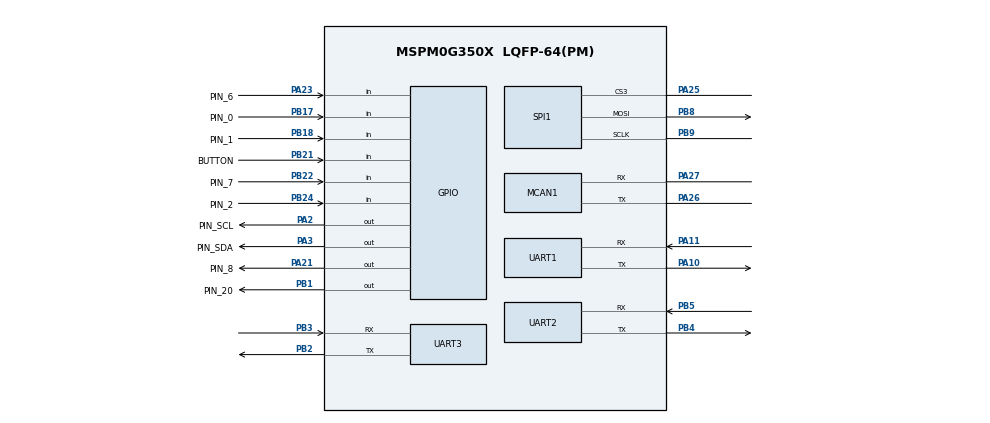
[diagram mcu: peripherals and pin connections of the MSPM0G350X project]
/**
 * @cliArgs --device "MSPM0G350X" --part "Default" --package "LQFP-64(PM)" --product "mspm0_sdk@2.05.01.01"
 * @versions {"tool":"1.24.0+4110"}
 */

/**
 * Import the modules used in this configuration.
 */
const GPIO   = scripting.addModule("/ti/driverlib/GPIO", {}, false);
const GPIO1  = GPIO.addInstance();
const GPIO2  = GPIO.addInstance();
const GPIO3  = GPIO.addInstance();
const GPIO4  = GPIO.addInstance();
const GPIO5  = GPIO.addInstance();
const GPIO6  = GPIO.addInstance();
const GPIO7  = GPIO.addInstance();
const GPIO8  = GPIO.addInstance();
const GPIO9  = GPIO.addInstance();
const GPIO10 = GPIO.addInstance();
const PWM    = scripting.addModule("/ti/driverlib/PWM", {}, false);
const PWM1   = PWM.addInstance();
const MCAN   = scripting.addModule("/ti/driverlib/MCAN", {}, false);
const MCAN1  = MCAN.addInstance();
const SPI    = scripting.addModule("/ti/driverlib/SPI", {}, false);
const SPI1   = SPI.addInstance();
const SYSCTL = scripting.addModule("/ti/driverlib/SYSCTL");
const TIMER  = scripting.addModule("/ti/driverlib/TIMER", {}, false);
const TIMER1 = TIMER.addInstance();
const TIMER2 = TIMER.addInstance();
const UART   = scripting.addModule("/ti/driverlib/UART", {}, false);
const UART1  = UART.addInstance();
const UART2  = UART.addInstance();
const UART3  = UART.addInstance();

/**
 * Write custom configuration values to the imported modules.
 */
const divider7       = system.clockTree["PLL_PDIV"];
divider7.divideValue = 2;

const divider9       = system.clockTree["UDIV"];
divider9.divideValue = 2;

const multiplier2         = system.clockTree["PLL_QDIV"];
multiplier2.multiplyValue = 5;

const mux8       = system.clockTree["HSCLKMUX"];
mux8.inputSelect = "HSCLKMUX_SYSPLL2X";

const mux2       = system.clockTree["CANCLKMUX"];
mux2.inputSelect = "CANCLKMUX_PLLCLK1_OUT";

GPIO1.$name                          = "GPIO_LCD";
GPIO1.associatedPins.create(4);
GPIO1.associatedPins[0].assignedPort = "PORTB";
GPIO1.associatedPins[0].assignedPin  = "10";
GPIO1.associatedPins[0].$name        = "PIN_RES";
GPIO1.associatedPins[1].$name        = "PIN_DC";
GPIO1.associatedPins[1].assignedPort = "PORTB";
GPIO1.associatedPins[1].assignedPin  = "11";
GPIO1.associatedPins[2].$name        = "PIN_CS";
GPIO1.associatedPins[2].assignedPort = "PORTB";
GPIO1.associatedPins[2].assignedPin  = "14";
GPIO1.associatedPins[3].$name        = "PIN_BLK";
GPIO1.associatedPins[3].assignedPort = "PORTB";
GPIO1.associatedPins[3].assignedPin  = "26";

const Board = scripting.addModule("/ti/driverlib/Board", {}, false);

GPIO2.$name                         = "motor_gpio";
GPIO2.port                          = "PORTA";
GPIO2.associatedPins.create(5);
GPIO2.associatedPins[0].$name       = "STBY";
GPIO2.associatedPins[0].assignedPin = "13";
GPIO2.associatedPins[1].$name       = "AIN1";
GPIO2.associatedPins[1].assignedPin = "15";
GPIO2.associatedPins[2].$name       = "AIN2";
GPIO2.associatedPins[2].assignedPin = "16";
GPIO2.associatedPins[3].$name       = "BIN1";
GPIO2.associatedPins[3].assignedPin = "17";
GPIO2.associatedPins[4].$name       = "BIN2";
GPIO2.associatedPins[4].assignedPin = "18";

GPIO3.$name                         = "ENCODERA";
GPIO3.port                          = "PORTA";
GPIO3.associatedPins.create(2);
GPIO3.associatedPins[0].$name       = "E1A";
GPIO3.associatedPins[0].direction   = "INPUT";
GPIO3.associatedPins[0].assignedPin = "12";
GPIO3.associatedPins[0].interruptEn = true;
GPIO3.associatedPins[0].polarity    = "RISE";
GPIO3.associatedPins[1].$name       = "E1B";
GPIO3.associatedPins[1].direction   = "INPUT";
GPIO3.associatedPins[1].assignedPin = "31";

GPIO4.$name                         = "ENCODERB";
GPIO4.port                          = "PORTB";
GPIO4.associatedPins.create(2);
GPIO4.associatedPins[0].$name       = "E2A";
GPIO4.associatedPins[0].direction   = "INPUT";
GPIO4.associatedPins[0].interruptEn = true;
GPIO4.associatedPins[0].polarity    = "RISE";
GPIO4.associatedPins[0].assignedPin = "12";
GPIO4.associatedPins[1].$name       = "E2B";
GPIO4.associatedPins[1].direction   = "INPUT";
GPIO4.associatedPins[1].assignedPin = "13";

GPIO5.$name                         = "GPIO_IIC";
GPIO5.associatedPins.create(2);
GPIO5.associatedPins[0].$name       = "PIN_SCL";
GPIO5.associatedPins[0].pin.$assign = "PA2";
GPIO5.associatedPins[1].$name       = "PIN_SDA";
GPIO5.associatedPins[1].pin.$assign = "PA3";

GPIO6.$name                              = "track";
GPIO6.associatedPins.create(8);
GPIO6.associatedPins[0].$name            = "PIN_0";
GPIO6.associatedPins[0].direction        = "INPUT";
GPIO6.associatedPins[0].assignedPort     = "PORTB";
GPIO6.associatedPins[0].assignedPin      = "17";
GPIO6.associatedPins[0].internalResistor = "PULL_UP";
GPIO6.associatedPins[0].pin.$assign      = "PB17";
GPIO6.associatedPins[1].$name            = "PIN_1";
GPIO6.associatedPins[1].direction        = "INPUT";
GPIO6.associatedPins[1].assignedPort     = "PORTB";
GPIO6.associatedPins[1].assignedPin      = "18";
GPIO6.associatedPins[1].internalResistor = "PULL_UP";
GPIO6.associatedPins[1].pin.$assign      = "PB18";
GPIO6.associatedPins[2].$name            = "PIN_2";
GPIO6.associatedPins[2].assignedPort     = "PORTB";
GPIO6.associatedPins[2].assignedPin      = "24";
GPIO6.associatedPins[2].direction        = "INPUT";
GPIO6.associatedPins[2].internalResistor = "PULL_UP";
GPIO6.associatedPins[2].pin.$assign      = "PB24";
GPIO6.associatedPins[3].$name            = "PIN_3";
GPIO6.associatedPins[3].assignedPort     = "PORTB";
GPIO6.associatedPins[3].assignedPin      = "25";
GPIO6.associatedPins[3].direction        = "INPUT";
GPIO6.associatedPins[3].internalResistor = "PULL_UP";
GPIO6.associatedPins[4].$name            = "PIN_4";
GPIO6.associatedPins[4].assignedPort     = "PORTA";
GPIO6.associatedPins[4].assignedPin      = "22";
GPIO6.associatedPins[4].direction        = "INPUT";
GPIO6.associatedPins[4].internalResistor = "PULL_UP";
GPIO6.associatedPins[5].$name            = "PIN_5";
GPIO6.associatedPins[5].direction        = "INPUT";
GPIO6.associatedPins[5].assignedPort     = "PORTB";
GPIO6.associatedPins[5].assignedPin      = "20";
GPIO6.associatedPins[5].internalResistor = "PULL_UP";
GPIO6.associatedPins[6].$name            = "PIN_6";
GPIO6.associatedPins[6].direction        = "INPUT";
GPIO6.associatedPins[6].assignedPort     = "PORTA";
GPIO6.associatedPins[6].assignedPin      = "23";
GPIO6.associatedPins[6].internalResistor = "PULL_UP";
GPIO6.associatedPins[6].pin.$assign      = "PA23";
GPIO6.associatedPins[7].$name            = "PIN_7";
GPIO6.associatedPins[7].direction        = "INPUT";
GPIO6.associatedPins[7].assignedPort     = "PORTB";
GPIO6.associatedPins[7].assignedPin      = "22";
GPIO6.associatedPins[7].internalResistor = "PULL_UP";
GPIO6.associatedPins[7].pin.$assign      = "PB22";

GPIO7.$name                              = "GPIO_KEY";
GPIO7.port                               = "PORTA";
GPIO7.associatedPins.create(3);
GPIO7.associatedPins[0].assignedPin      = "28";
GPIO7.associatedPins[0].$name            = "KEY_2";
GPIO7.associatedPins[0].direction        = "INPUT";
GPIO7.associatedPins[0].internalResistor = "PULL_UP";
GPIO7.associatedPins[1].$name            = "KEY_1";
GPIO7.associatedPins[1].direction        = "INPUT";
GPIO7.associatedPins[1].assignedPin      = "8";
GPIO7.associatedPins[1].internalResistor = "PULL_UP";
GPIO7.associatedPins[2].$name            = "KEY_3";
GPIO7.associatedPins[2].direction        = "INPUT";
GPIO7.associatedPins[2].assignedPin      = "9";
GPIO7.associatedPins[2].internalResistor = "PULL_UP";

GPIO8.$name                          = "GPIO_BEEPER";
GPIO8.port                           = "PORTB";
GPIO8.associatedPins[0].$name        = "PIN_20";
GPIO8.associatedPins[0].initialValue = "SET";
GPIO8.associatedPins[0].assignedPin  = "1";
GPIO8.associatedPins[0].pin.$assign  = "PB1";

GPIO9.$name                         = "GPIO_LED";
GPIO9.port                          = "PORTA";
GPIO9.associatedPins[0].$name       = "PIN_8";
GPIO9.associatedPins[0].assignedPin = "21";
GPIO9.associatedPins[0].pin.$assign = "PA21";

GPIO10.$name                              = "START_KEY";
GPIO10.port                               = "PORTB";
GPIO10.associatedPins.create(1);
GPIO10.associatedPins[0].$name            = "BUTTON";
GPIO10.associatedPins[0].direction        = "INPUT";
GPIO10.associatedPins[0].assignedPin      = "21";
GPIO10.associatedPins[0].internalResistor = "PULL_UP";
GPIO10.associatedPins[0].pin.$assign      = "PB21";

PWM1.$name                              = "PWM_A";
PWM1.clockDivider                       = 8;
PWM1.timerStartTimer                    = true;
PWM1.timerCount                         = 10000;
PWM1.peripheral.$assign                 = "TIMA0";
PWM1.PWM_CHANNEL_0.$name                = "ti_driverlib_pwm_PWMTimerCC0";
PWM1.PWM_CHANNEL_0.dutyCycle            = 50;
PWM1.PWM_CHANNEL_1.$name                = "ti_driverlib_pwm_PWMTimerCC1";
PWM1.PWM_CHANNEL_1.dutyCycle            = 50;
PWM1.ccp0PinConfig.direction            = scripting.forceWrite("OUTPUT");
PWM1.ccp0PinConfig.hideOutputInversion  = scripting.forceWrite(false);
PWM1.ccp0PinConfig.onlyInternalResistor = scripting.forceWrite(false);
PWM1.ccp0PinConfig.passedPeripheralType = scripting.forceWrite("Digital");
PWM1.ccp0PinConfig.$name                = "ti_driverlib_gpio_GPIOPinGeneric1";
PWM1.ccp1PinConfig.direction            = scripting.forceWrite("OUTPUT");
PWM1.ccp1PinConfig.hideOutputInversion  = scripting.forceWrite(false);
PWM1.ccp1PinConfig.onlyInternalResistor = scripting.forceWrite(false);
PWM1.ccp1PinConfig.passedPeripheralType = scripting.forceWrite("Digital");
PWM1.ccp1PinConfig.$name                = "ti_driverlib_gpio_GPIOPinGeneric6";

SPI1.direction                          = "PICO";
SPI1.enableCDMode                       = true;
SPI1.targetBitRate                      = 32000000;
SPI1.frameFormat                        = "MOTO3";
SPI1.$name                              = "SPI_LCD";
SPI1.sclkPinConfig.direction            = scripting.forceWrite("OUTPUT");
SPI1.sclkPinConfig.onlyInternalResistor = scripting.forceWrite(false);
SPI1.sclkPinConfig.passedPeripheralType = scripting.forceWrite("Digital");
SPI1.sclkPinConfig.$name                = "ti_driverlib_gpio_GPIOPinGeneric0";
SPI1.mosiPinConfig.direction            = scripting.forceWrite("OUTPUT");
SPI1.mosiPinConfig.hideOutputInversion  = scripting.forceWrite(false);
SPI1.mosiPinConfig.onlyInternalResistor = scripting.forceWrite(false);
SPI1.mosiPinConfig.passedPeripheralType = scripting.forceWrite("Digital");
SPI1.mosiPinConfig.$name                = "ti_driverlib_gpio_GPIOPinGeneric2";
SPI1.cs3PinConfig.direction             = scripting.forceWrite("OUTPUT");
SPI1.cs3PinConfig.hideOutputInversion   = scripting.forceWrite(false);
SPI1.cs3PinConfig.onlyInternalResistor  = scripting.forceWrite(false);
SPI1.cs3PinConfig.passedPeripheralType  = scripting.forceWrite("Digital");
SPI1.cs3PinConfig.$name                 = "ti_driverlib_gpio_GPIOPinGeneric3";
SPI1.peripheral.$assign                 = "SPI1";
SPI1.peripheral.sclkPin.$assign         = "PB9";
SPI1.peripheral.mosiPin.$assign         = "PB8";
SPI1.peripheral.cs3Pin.$assign          = "PA25";

MCAN1.$name                    = "MCAN0";
MCAN1.fdMode                   = false;
MCAN1.brsEnable                = false;
MCAN1.tdcEnable                = false;
MCAN1.desiredNomRate           = 1000;
MCAN1.spPercent                = 87.5;
MCAN1.can_clk_freq_div         = "1";
MCAN1.additionalCoreConfig     = true;
MCAN1.rrfe                     = true;
MCAN1.rrfs                     = true;
MCAN1.anfe                     = "0";
MCAN1.anfs                     = "0";
MCAN1.flssa                    = 0;
MCAN1.lss                      = 0;
MCAN1.flesa                    = 0;
MCAN1.lse                      = 0;
MCAN1.txStartAddr              = 0;
MCAN1.txBufNum                 = 1;
MCAN1.txFIFOSize               = 0;
MCAN1.txBufElemSize            = "DL_MCAN_ELEM_SIZE_8BYTES";
MCAN1.txEventFIFOStartAddr     = 16;
MCAN1.txEventFIFOSize          = 0;
MCAN1.txEventFIFOWaterMark     = 0;
MCAN1.rxFIFO0startAddr         = 16;
MCAN1.rxFIFO0size              = 16;
MCAN1.rxFIFO0waterMark         = 0;
MCAN1.rxFIFO0ElemSize          = "DL_MCAN_ELEM_SIZE_8BYTES";
MCAN1.rxFIFO1startAddr         = 272;
MCAN1.rxFIFO1size              = 0;
MCAN1.rxFIFO1waterMark         = 0;
MCAN1.rxFIFO1ElemSize          = "DL_MCAN_ELEM_SIZE_8BYTES";
MCAN1.rxBufStartAddr           = 272;
MCAN1.rxBufElemSize            = "DL_MCAN_ELEM_SIZE_8BYTES";
MCAN1.enableInterrupt          = true;
MCAN1.interruptFlags           = ["DL_MCAN_INTERRUPT_RF0N","DL_MCAN_INTERRUPT_RF0F","DL_MCAN_INTERRUPT_RF0L","DL_MCAN_INTERRUPT_TC","DL_MCAN_INTERRUPT_MRAF","DL_MCAN_INTERRUPT_ELO","DL_MCAN_INTERRUPT_EP","DL_MCAN_INTERRUPT_EW","DL_MCAN_INTERRUPT_BO","DL_MCAN_INTERRUPT_PEA","DL_MCAN_INTERRUPT_PED"];
MCAN1.interruptLine            = ["DL_MCAN_INTR_LINE_NUM_1"];
MCAN1.interruptLine1Flag       = ["DL_MCAN_INTR_MASK_ALL"];
MCAN1.m0interrupts             = ["DL_MCAN_MSP_INTERRUPT_LINE1"];
MCAN1.txPinConfig.$name        = "hball_can_tx_pin";
MCAN1.rxPinConfig.$name        = "hball_can_rx_pin";
MCAN1.peripheral.$assign       = "CANFD0";
MCAN1.peripheral.txPin.$assign = "PA26";
MCAN1.peripheral.rxPin.$assign = "PA27";

SYSCTL.forceDefaultClkConfig = true;
SYSCTL.clockTreeEn           = true;
SYSCTL.SYSPLL_CLK1En         = true;
SYSCTL.SYSPLL_CLK1Div        = 0;
scripting.suppress("For best practices when the CPUCLK is running at 32MHz and above, clear the flash status bit using DL_FlashCTL_executeClearStatus\\(\\) before executing any flash operation\\. Otherwise there may be false positives\\.", SYSCTL);

TIMER1.$name              = "TIMER_0";
TIMER1.timerClkDiv        = 8;
TIMER1.timerMode          = "PERIODIC";
TIMER1.timerClkPrescale   = 200;
TIMER1.timerStartTimer    = true;
TIMER1.interrupts         = ["ZERO"];
TIMER1.interruptPriority  = "1";
TIMER1.timerPeriod        = "20ms";
TIMER1.peripheral.$assign = "TIMA1";

TIMER2.$name             = "TIMER_1";
TIMER2.timerStartTimer   = true;
TIMER2.timerClkPrescale  = 8;
TIMER2.timerPeriod       = "10ms";
TIMER2.interrupts        = ["ZERO"];
TIMER2.timerMode         = "PERIODIC";
TIMER2.interruptPriority = "1";

UART1.enabledInterrupts                = ["RX"];
UART1.interruptPriority                = "1";
UART1.$name                            = "UART_1";
UART1.peripheral.rxPin.$assign         = "PA11";
UART1.peripheral.txPin.$assign         = "PA10";
UART1.txPinConfig.direction            = scripting.forceWrite("OUTPUT");
UART1.txPinConfig.hideOutputInversion  = scripting.forceWrite(false);
UART1.txPinConfig.onlyInternalResistor = scripting.forceWrite(false);
UART1.txPinConfig.passedPeripheralType = scripting.forceWrite("Digital");
UART1.txPinConfig.$name                = "ti_driverlib_gpio_GPIOPinGeneric4";
UART1.rxPinConfig.hideOutputInversion  = scripting.forceWrite(false);
UART1.rxPinConfig.onlyInternalResistor = scripting.forceWrite(false);
UART1.rxPinConfig.passedPeripheralType = scripting.forceWrite("Digital");
UART1.rxPinConfig.$name                = "ti_driverlib_gpio_GPIOPinGeneric5";

UART2.enabledInterrupts                = ["RX"];
UART2.$name                            = "UART_0";
UART2.peripheral.$assign               = "UART1";
UART2.peripheral.rxPin.$assign         = "PB5";
UART2.peripheral.txPin.$assign         = "PB4";
UART2.txPinConfig.direction            = scripting.forceWrite("OUTPUT");
UART2.txPinConfig.hideOutputInversion  = scripting.forceWrite(false);
UART2.txPinConfig.onlyInternalResistor = scripting.forceWrite(false);
UART2.txPinConfig.passedPeripheralType = scripting.forceWrite("Digital");
UART2.txPinConfig.$name                = "ti_driverlib_gpio_GPIOPinGeneric7";
UART2.rxPinConfig.hideOutputInversion  = scripting.forceWrite(false);
UART2.rxPinConfig.onlyInternalResistor = scripting.forceWrite(false);
UART2.rxPinConfig.passedPeripheralType = scripting.forceWrite("Digital");
UART2.rxPinConfig.$name                = "ti_driverlib_gpio_GPIOPinGeneric8";

UART3.$name                            = "UART_WIT";
UART3.targetBaudRate                   = 9600;
UART3.enableFIFO                       = true;
UART3.rxTimeoutValue                   = 2;
UART3.uartClkDiv                       = "2";
UART3.enabledInterrupts                = ["RX_TIMEOUT_ERROR"];
UART3.enabledDMARXTriggers             = "DL_UART_DMA_INTERRUPT_RX";
UART3.interruptPriority                = "0";
UART3.peripheral.$assign               = "UART3";
UART3.peripheral.rxPin.$assign         = "PB3";
UART3.peripheral.txPin.$assign         = "PB2";
UART3.txPinConfig.direction            = scripting.forceWrite("OUTPUT");
UART3.txPinConfig.hideOutputInversion  = scripting.forceWrite(false);
UART3.txPinConfig.onlyInternalResistor = scripting.forceWrite(false);
UART3.txPinConfig.passedPeripheralType = scripting.forceWrite("Digital");
UART3.txPinConfig.$name                = "ti_driverlib_gpio_GPIOPinGeneric9";
UART3.rxPinConfig.hideOutputInversion  = scripting.forceWrite(false);
UART3.rxPinConfig.onlyInternalResistor = scripting.forceWrite(false);
UART3.rxPinConfig.passedPeripheralType = scripting.forceWrite("Digital");
UART3.rxPinConfig.$name                = "ti_driverlib_gpio_GPIOPinGeneric10";
UART3.DMA_CHANNEL_RX.$name             = "DMA_WIT";
UART3.DMA_CHANNEL_RX.addressMode       = "f2b";
UART3.DMA_CHANNEL_RX.srcLength         = "BYTE";
UART3.DMA_CHANNEL_RX.dstLength         = "BYTE";

/**
 * Pinmux solution for unlocked pins/peripherals. This ensures that minor changes to the automatic solver in a future
 * version of the tool will not impact the pinmux you originally saw.  These lines can be completely deleted in order to
 * re-solve from scratch.
 */
GPIO1.associatedPins[0].pin.$suggestSolution     = "PB10";
GPIO1.associatedPins[1].pin.$suggestSolution     = "PB11";
GPIO1.associatedPins[2].pin.$suggestSolution     = "PB14";
GPIO1.associatedPins[3].pin.$suggestSolution     = "PB26";
Board.peripheral.$suggestSolution                = "DEBUGSS";
Board.peripheral.swclkPin.$suggestSolution       = "PA20";
Board.peripheral.swdioPin.$suggestSolution       = "PA19";
GPIO2.associatedPins[0].pin.$suggestSolution     = "PA13";
GPIO2.associatedPins[1].pin.$suggestSolution     = "PA15";
GPIO2.associatedPins[2].pin.$suggestSolution     = "PA16";
GPIO2.associatedPins[3].pin.$suggestSolution     = "PA17";
GPIO2.associatedPins[4].pin.$suggestSolution     = "PA18";
GPIO3.associatedPins[0].pin.$suggestSolution     = "PA12";
GPIO3.associatedPins[1].pin.$suggestSolution     = "PA31";
GPIO4.associatedPins[0].pin.$suggestSolution     = "PB12";
GPIO4.associatedPins[1].pin.$suggestSolution     = "PB13";
GPIO6.associatedPins[3].pin.$suggestSolution     = "PB25";
GPIO6.associatedPins[4].pin.$suggestSolution     = "PA22";
GPIO6.associatedPins[5].pin.$suggestSolution     = "PB20";
GPIO7.associatedPins[0].pin.$suggestSolution     = "PA28";
GPIO7.associatedPins[1].pin.$suggestSolution     = "PA8";
GPIO7.associatedPins[2].pin.$suggestSolution     = "PA9";
PWM1.peripheral.ccp0Pin.$suggestSolution         = "PA0";
PWM1.peripheral.ccp1Pin.$suggestSolution         = "PA1";
TIMER2.peripheral.$suggestSolution               = "TIMG0";
UART1.peripheral.$suggestSolution                = "UART0";
UART3.DMA_CHANNEL_RX.peripheral.$suggestSolution = "DMA_CH0";
